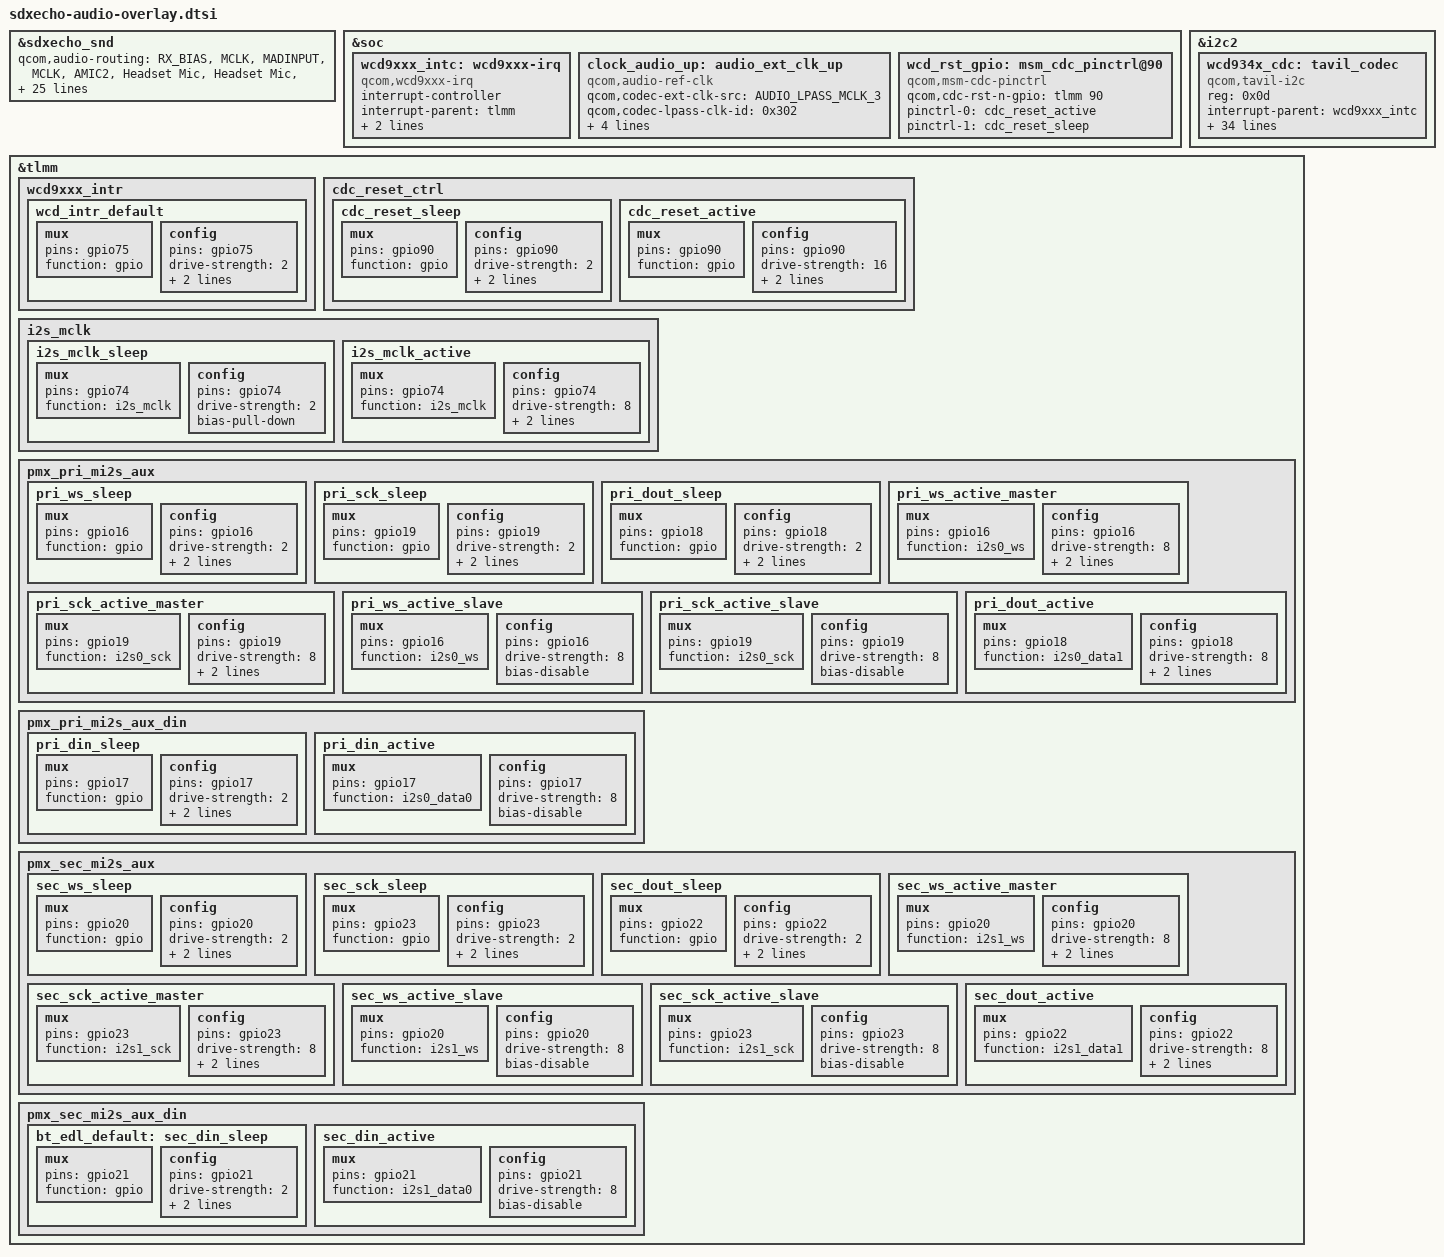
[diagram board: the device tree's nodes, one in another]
// SPDX-License-Identifier: BSD-3-Clause
/*
 * Copyright (c) Qualcomm Technologies, Inc. and/or its subsidiaries.
 */

#include "sdxecho-wcd.dtsi"
#include "sdxecho-wsa881x.dtsi"
#include "bindings/qcom,audio-ext-clk.h"
#include <dt-bindings/arm/qcom_dma_heap_dt_constants.h>

&sdxecho_snd {
	qcom,audio-routing =
		"RX_BIAS", "MCLK",
		"MADINPUT", "MCLK",
		"AMIC2", "Headset Mic",
		"Headset Mic", "MIC BIAS2",
		"AMIC3", "ANCRight Headset Mic",
		"ANCRight Headset Mic", "MIC BIAS2",
		"AMIC4", "ANCLeft Headset Mic",
		"ANCLeft Headset Mic", "MIC BIAS2",
		"AMIC5", "Handset Mic",
		"Handset Mic", "MIC BIAS3",
		"DMIC1", "Digital Mic1",
		"DMIC1", "MIC BIAS1",
		"DMIC2", "Digital Mic2",
		"DMIC2", "MIC BIAS3",
		"DMIC3", "Digital Mic3",
		"DMIC3", "MIC BIAS3",
		"DMIC4", "Digital Mic4",
		"DMIC4", "MIC BIAS4",
		"DMIC5", "Digital Mic5",
		"DMIC5", "MIC BIAS4",
		"SpkrLeft IN", "SPK1 OUT";

	qcom,msm-mbhc-hphl-swh = <1>;
	qcom,msm-mbhc-gnd-swh = <1>;
	qcom,msm-mbhc-hs-mic-max-threshold-mv = <1700>;
	qcom,msm-mbhc-hs-mic-min-threshold-mv = <50>;
	qcom,cdc-ext-clk-rate = <9600000>;
	qcom,tavil-mclk-clk-freq = <9600000>;

	asoc-codec = <&stub_codec>, <&wsa881x_0214>;
	asoc-codec-names = "msm-stub-codec.1", "wsa-codec.1";

	qcom,wsa-max-devs = <1>;
	qcom,swr-num-dev = <1>;
	qcom,wsa-devs = <&wsa881x_0214>;
	qcom,wsa-aux-dev-prefix = "SpkrLeft";
	qcom,msm_audio_ssr_devs = <&audio_gpr>, <&wcd934x_cdc>;
};

&soc {
	wcd9xxx_intc: wcd9xxx-irq {
		status = "ok";
		compatible = "qcom,wcd9xxx-irq";
		interrupt-controller;
		#interrupt-cells = <1>;
		interrupt-parent = <&tlmm>;
		qcom,gpio-connect = <&tlmm 75 0>;
		pinctrl-names = "default";
		pinctrl-0 = <&wcd_intr_default>;
	};

	clock_audio_up: audio_ext_clk_up {
		compatible = "qcom,audio-ref-clk";
		qcom,codec-ext-clk-src = <AUDIO_LPASS_MCLK_3>;
		qcom,codec-lpass-clk-id = <0x302>;
		qcom,codec-lpass-ext-clk-freq = <9600000>;
		qcom,use-pinctrl = <1>;
		pinctrl-names = "sleep", "active";
		pinctrl-0 = <&i2s_mclk_sleep>;
		pinctrl-1 = <&i2s_mclk_active>;
		#clock-cells = <1>;
	};

	wcd_rst_gpio: msm_cdc_pinctrl@90 {
		compatible = "qcom,msm-cdc-pinctrl";
		qcom,cdc-rst-n-gpio = <&tlmm 90 0>;
		pinctrl-names = "aud_active", "aud_sleep";
		pinctrl-0 = <&cdc_reset_active>;
		pinctrl-1 = <&cdc_reset_sleep>;
	};
};

&i2c2 {
	status = "ok";
	wcd934x_cdc: tavil_codec {
		compatible = "qcom,tavil-i2c";
		reg = <0x0d>;

		interrupt-parent = <&wcd9xxx_intc>;
		interrupts = <0 1 2 3 4 5 6 7 8 9 10 11 12 13 14 15 16
			      17 18 19 20 21 22 23 24 25 26 27 28 29
			      30 31>;

		qcom,wcd-rst-gpio-node = <&wcd_rst_gpio>;

		clock-names = "wcd_clk";
		clocks = <&clock_audio_up 0>;

		cdc-vdd-buck-supply = <&vreg_l6b_1p8>;
		qcom,cdc-vdd-buck-voltage = <1800000 1800000>;
		qcom,cdc-vdd-buck-current = <650000>;
		qcom,cdc-vdd-buck-lpm-supported = <1>;

		cdc-buck-sido-supply = <&vreg_l6b_1p8>;
		qcom,cdc-buck-sido-voltage = <1800000 1800000>;
		qcom,cdc-buck-sido-current = <500000>;
		qcom,cdc-buck-sido-lpm-supported = <1>;

		cdc-vdd-tx-h-supply = <&vreg_l6b_1p8>;
		qcom,cdc-vdd-tx-h-voltage = <1800000 1800000>;
		qcom,cdc-vdd-tx-h-current = <25000>;
		qcom,cdc-vdd-tx-h-lpm-supported = <1>;

		cdc-vdd-rx-h-supply = <&vreg_l6b_1p8>;
		qcom,cdc-vdd-rx-h-voltage = <1800000 1800000>;
		qcom,cdc-vdd-rx-h-current = <25000>;
		qcom,cdc-vdd-rx-h-lpm-supported = <1>;

		cdc-vddpx-1-supply = <&vreg_l6b_1p8>;
		qcom,cdc-vddpx-1-voltage = <1800000 1800000>;
		qcom,cdc-vddpx-1-current = <10000>;
		qcom,cdc-vddpx-1-lpm-supported = <1>;

		qcom,cdc-static-supplies = "cdc-vdd-buck",
					   "cdc-buck-sido",
					   "cdc-vdd-tx-h",
					   "cdc-vdd-rx-h",
					   "cdc-vddpx-1";

		qcom,cdc-micbias1-mv = <1800>;
		qcom,cdc-micbias2-mv = <1800>;
		qcom,cdc-micbias3-mv = <1800>;
		qcom,cdc-micbias4-mv = <1800>;

		qcom,cdc-mclk-clk-rate = <9600000>;
		qcom,cdc-dmic-sample-rate = <4800000>;

		qcom,wdsp-cmpnt-dev-name = "tavil_codec";
	};
};

&tlmm {
	wcd9xxx_intr {
		wcd_intr_default: wcd_intr_default {
			mux {
				pins = "gpio75";
				function = "gpio";
			};

			config {
				pins = "gpio75";
				drive-strength = <2>; /* 2 mA */
				bias-pull-down; /* pull down */
				input-enable;
			};
		};
	};

	cdc_reset_ctrl {
		cdc_reset_sleep: cdc_reset_sleep {
			mux {
				pins = "gpio90";
				function = "gpio";
			};

			config {
				pins = "gpio90";
				drive-strength = <2>;
				bias-disable;
				output-low;
			};
		};

		cdc_reset_active:cdc_reset_active {
			mux {
				pins = "gpio90";
				function = "gpio";
			};

			config {
				pins = "gpio90";
				drive-strength = <16>;
				bias-pull-up;
				output-high;
			};
		};
	};

	i2s_mclk {
		i2s_mclk_sleep: i2s_mclk_sleep {
			mux {
				pins = "gpio74";
				function = "i2s_mclk";
			};

			config {
				pins = "gpio74";
				drive-strength = <2>;	/* 2 mA */
				bias-pull-down;		/* PULL DOWN */
			};
		};

		i2s_mclk_active: i2s_mclk_active {
			mux {
				pins = "gpio74";
				function = "i2s_mclk";
			};

			config {
				pins = "gpio74";
				drive-strength = <8>;	/* 8 mA */
				bias-disable;		/* NO PULL*/
				output-high;
			};
		};
	};

	pmx_pri_mi2s_aux {
		pri_ws_sleep: pri_ws_sleep {
			mux {
				pins = "gpio16";
				function = "gpio";
			};

			config {
				pins = "gpio16";
				drive-strength = <2>;	/* 2 mA */
				bias-pull-down;		/* PULL DOWN */
				input-enable;
			};
		};

		pri_sck_sleep: pri_sck_sleep {
			mux {
				pins = "gpio19";
				function = "gpio";
			};

			config {
				pins = "gpio19";
				drive-strength = <2>;	/* 2 mA */
				bias-pull-down;		/* PULL DOWN */
				input-enable;
			};
		};

		pri_dout_sleep: pri_dout_sleep {
			mux {
				pins = "gpio18";
				function = "gpio";
			};

			config {
				pins = "gpio18";
				drive-strength = <2>;	/* 2 mA */
				bias-pull-down;		/* PULL DOWN */
				input-enable;
			};
		};

		pri_ws_active_master: pri_ws_active_master {
			mux {
				pins = "gpio16";
				function = "i2s0_ws";
			};

			config {
				pins = "gpio16";
				drive-strength = <8>;	/* 8 mA */
				bias-disable;		/* NO PULL*/
				output-high;
			};
		};

		pri_sck_active_master: pri_sck_active_master {
			mux {
				pins = "gpio19";
				function = "i2s0_sck";
			};

			config {
				pins = "gpio19";
				drive-strength = <8>;	/* 8 mA */
				bias-disable;		/* NO PULL*/
				output-high;
			};
		};

		pri_ws_active_slave: pri_ws_active_slave {
			mux {
				pins = "gpio16";
				function = "i2s0_ws";
			};

			config {
				pins = "gpio16";
				drive-strength = <8>;	/* 8 mA */
				bias-disable;		/* NO PULL*/
			};
		};

		pri_sck_active_slave: pri_sck_active_slave {
			mux {
				pins = "gpio19";
				function = "i2s0_sck";
			};

			config {
				pins = "gpio19";
				drive-strength = <8>;	/* 8 mA */
				bias-disable;		/* NO PULL*/
			};
		};

		pri_dout_active: pri_dout_active {
			mux {
				pins = "gpio18";
				function = "i2s0_data1";
			};

			config {
				pins = "gpio18";
				drive-strength = <8>;	/* 8 mA */
				bias-disable;		/* NO PULL*/
				output-high;
			};
		};
	};

	pmx_pri_mi2s_aux_din {
		pri_din_sleep: pri_din_sleep {
			mux {
				pins = "gpio17";
				function = "gpio";
			};

			config {
				pins = "gpio17";
				drive-strength = <2>;	/* 2 mA */
				bias-pull-down;		/* PULL DOWN */
				input-enable;
			};
		};

		pri_din_active: pri_din_active {
			mux {
				pins = "gpio17";
				function = "i2s0_data0";
			};

			config {
				pins = "gpio17";
				drive-strength = <8>;	/* 8 mA */
				bias-disable;		/* NO PULL */
			};
		};
	};

	pmx_sec_mi2s_aux {
		sec_ws_sleep: sec_ws_sleep {
			mux {
				pins = "gpio20";
				function = "gpio";
			};

			config {
				pins = "gpio20";
				drive-strength = <2>;	/* 2 mA */
				bias-pull-down;		/* PULL DOWN */
				input-enable;
			};
		};

		sec_sck_sleep: sec_sck_sleep {
			mux {
				pins = "gpio23";
				function = "gpio";
			};

			config {
				pins = "gpio23";
				drive-strength = <2>;	/* 2 mA */
				bias-pull-down;		/* PULL DOWN */
				input-enable;
			};
		};

		sec_dout_sleep: sec_dout_sleep {
			mux {
				pins = "gpio22";
				function = "gpio";
			};

			config {
				pins = "gpio22";
				drive-strength = <2>;	/* 2 mA */
				bias-pull-down;		/* PULL DOWN */
				input-enable;
			};
		};

		sec_ws_active_master: sec_ws_active_master {
			mux {
				pins = "gpio20";
				function = "i2s1_ws";
			};

			config {
				pins = "gpio20";
				drive-strength = <8>;	/* 8 mA */
				bias-disable;		/* NO PULL*/
				output-high;
			};
		};

		sec_sck_active_master: sec_sck_active_master {
			mux {
				pins = "gpio23";
				function = "i2s1_sck";
			};

			config {
				pins = "gpio23";
				drive-strength = <8>;	/* 8 mA */
				bias-disable;		/* NO PULL*/
				output-high;
			};
		};

		sec_ws_active_slave: sec_ws_active_slave {
			mux {
				pins = "gpio20";
				function = "i2s1_ws";
			};

			config {
				pins = "gpio20";
				drive-strength = <8>;	/* 8 mA */
				bias-disable;		/* NO PULL*/
			};
		};

		sec_sck_active_slave: sec_sck_active_slave {
			mux {
				pins = "gpio23";
				function = "i2s1_sck";
			};

			config {
				pins = "gpio23";
				drive-strength = <8>;	/* 8 mA */
				bias-disable;		/* NO PULL*/
			};
		};

		sec_dout_active: sec_dout_active {
			mux {
				pins = "gpio22";
				function = "i2s1_data1";
			};

			config {
				pins = "gpio22";
				drive-strength = <8>;	/* 8 mA */
				bias-disable;		/* NO PULL*/
				output-high;
			};
		};
	};

	pmx_sec_mi2s_aux_din {
		bt_edl_default: sec_din_sleep: sec_din_sleep {
			mux {
				pins = "gpio21";
				function = "gpio";
			};

			config {
				pins = "gpio21";
				drive-strength = <2>;	/* 2 mA */
				bias-disable;		/* NO PULL */
				input-enable;
			};
		};

		sec_din_active: sec_din_active {
			mux {
				pins = "gpio21";
				function = "i2s1_data0";
			};

			config {
				pins = "gpio21";
				drive-strength = <8>;	/* 8 mA */
				bias-disable;		/* NO PULL */
			};
		};
	};
};

